# cslr_mcspi register map
Vendor: Texas Instruments
Peripheral module from a debugger description file (folder C5517).
Address unit: 16 bits
Registers are 16-bit, access not given, reset 0x0 unless marked. A register's access mark holds for its fields unless they carry their own. Offsets are as the file gives them; lines under a group give offsets from that group; [hi:lo] are bit positions; {n}, {i} and the like mark numbered series; 'fields as' and 'values as' point back to an identical list; <NAME> marks a mode.

## MCSPI — Master slave Multichannel Serial Port Interface
0x100 REVISIONL reset 0x2B — This register contains the hard coded RTL revision number
  [7:0] REV ro — IP revision [7:4] Major revision [3:0] Minor revision
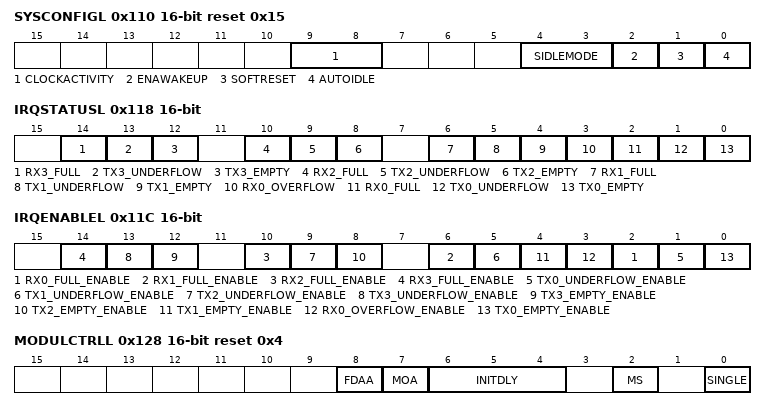
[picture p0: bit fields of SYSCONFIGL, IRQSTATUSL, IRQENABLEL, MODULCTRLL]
0x110 SYSCONFIGL reset 0x15 — This register allows controlling various parameters of the OCP interface. It is not sensitive to soft reset.
  [9:8] CLOCKACTIVITY rw — Clocks activity during wake up mode period
    0=ACT0 (OCP and Functional clocks may be switched off); 1=ACT1 (OCP clock is maintained. Functional clock may be switched-off); 2=ACT2 (Functional clock is maintained. OCP clock may be switched-off); 3=ACT3 (OCP and Functional clocks are maintained)
  [4:3] SIDLEMODE rw — Power management
    0=MODE0 (If an idle request is detected, the McSPI acknowledges it unconditionally and goes in Inactive mode. Interrupt, DMA requests and wake up lines are unconditionally de-asserted and the module wakeup capability is deactivated even if the bit MCSPI_SYSCONFIG[EnaWakeUp] is set); 1=MODE1 (If an idle request is detected, the request is ignored and the module does not switch to wake up mode, and keeps on behaving normally); 2=MODE2 (Smart-idle mode: local target's idle state eventually follows (acknowledges) the system's idle requests, depending on the IP module's internal requirements. IP module shall not generate (IRQ- or DMA-request-related) wakeup events); 3=MODE3 (IP module may generate (IRQ- or DMA-request-related) wakeup events when in idle state. Mode is only relevant if the appropriate IP module "swakeup" output(s) is (are) implemented)
  [2] ENAWAKEUP rw — WakeUp feature control
    0=DISABLE (WakeUp capability is disabled); 1=ENABLE (WakeUp capability is enabled)
  [1] SOFTRESET rw — Software reset. During reads it always returns 0.
    0=NORMAL (Normal mode); 1=TRIGGER (Set this bit to 1 to trigger a module reset.The bit is automatically reset by the hardware)
  [0] AUTOIDLE rw — Internal OCP Clock gating strategy
    0=FREERUN (OCP clock is free-running); 1=AUTO (Automatic OCP clock gating strategy is applied, based on the OCP interface activity)
0x114 SYSSTATUSL — This register provides status information about the module excluding the interrupt status information
  [0] RESETDONE ro — Internal Reset Monitoring
    0=ONGOING (Internal module reset is on-going); 1=COMPLETE (Reset completed)
0x118 IRQSTATUSL — The interrupt status regroups all the status of the module internal events that can generate an interrupt
  [all] fields
    0=FALSEEVT (w:Event status bit unchanged ,False event); 1=PENDINGEVT (w:Event status bit is reset ,r: Event is pending)
  [14] RX3_FULL rw — Receiver register is full or almost full. Only when Channel 3 is enabled
  [13] TX3_UNDERFLOW rw — Transmitter register underflow. Only when Channel 3 is enabled.
  [12] TX3_EMPTY rw — Transmitter register is empty or almost empty.
  [10] RX2_FULL rw — Receiver register full or almost full. Channel 2
  [9] TX2_UNDERFLOW rw — Transmitter register underflow. Channel 2
  [8] TX2_EMPTY rw — Transmitter register empty or almost empty. Channel 2
  [6] RX1_FULL rw — Receiver register full or almost full. Channel 1
  [5] TX1_UNDERFLOW rw — Transmitter register underflow. Channel 1
  [4] TX1_EMPTY rw — Transmitter register empty or almost empty. Channel 1
  [3] RX0_OVERFLOW rw — Receiver register overflow (slave mode only). Channel 0
  [2] RX0_FULL rw — Receiver register full or almost full. Channel 0
  [1] TX0_UNDERFLOW rw — Transmitter register underflow.Channel 0
  [0] TX0_EMPTY rw — Transmitter register empty or almost empty.Channel 0
0x119 IRQSTATUSU — The interrupt status regroups all the status of the module internal events that can generate an interrupt
  [1] EOW rw — End of word count event when a channel is enabled using the FIFO buffer and the channel had sent the number of SPI word defined by MCSPI_XFERLEVEL[WCNT].
    0=NOCHNAGE (w:Event status bit unchanged); 1=BITRESET (w:Event status bit is reset)
0x11C IRQENABLEL — This register allows to enable/disable the module internal sources of interrupt, on an event-by-event basis.
  [all] fields
    0=DISABLE (Interrupt disabled); 1=ENABLE (Interrupt enabled)
  [4n+2] RX{n}_FULL_ENABLE rw (n=0..3) — Receiver register Full or almost full Interrupt Enable. Ch {n}
  [4n+1] TX{n}_UNDERFLOW_ENABLE rw (n=0..3) — Transmitter register Underflow Interrupt Enable. Ch {n}
  [12] TX3_EMPTY_ENABLE rw — Transmitter register Empty or almost empty Interrupt Enable. Ch3
  [8] TX2_EMPTY_ENABLE rw — Transmitter register Empty or almost empty Interrupt Enable. Ch 2
  [4] TX1_EMPTY_ENABLE rw — Transmitter register Empty or almost empty Interrupt Enable. Ch 1
  [3] RX0_OVERFLOW_ENABLE rw — Receiver register Overflow Interrupt Enable. Ch 0
  [0] TX0_EMPTY_ENABLE rw — Transmitter register Empty or almost empty Interrupt Enable. Ch 0
0x11D IRQENABLEU — This register allows to enable/disable the module internal sources of interrupt, on an event-by-event basis.
  [1] EOWE rw — End of Word count Interrupt Enable
    0=DISABLE (Interrupt disabled); 1=ENABLE (Interrupt enabled)
0x120 WAKEUPENABLEL — The wakeup enable register allows to enable/disable the module internal sources of wakeup on event-by-event basis.
0x128 MODULCTRLL reset 0x4 — This register is dedicated to the configuration of the serial port interface.
  [8] FDAA rw — FIFO DMA Address 256-bit aligned
    0=TXREG (FIFO data managed by MCSPI_TX(i) and MCSPI_RX(i) registers); 1=DAFTXREG (FIFO data managed by MCSPI_DAFTX and MCSPI_DAFRX registers)
  [7] MOA rw — Multiple word ocp access
    0=DISABLE (Multiple word access disabled); 1=ENABLE (Multiple word access enabled with FIFO)
  [6:4] INITDLY rw — Initial spi delay for first transfer
    0=NODELAY (No delay for first spi transfer.); 1=4CLK (The controller wait 4 spi bus clock); 2=8CLK (The controller wait 8 spi bus clock); 3=16CLK (The controller wait 16 spi bus clock); 4=32CLK (The controller wait 32 spi bus clock)
  [2] MS rw — Master/ Slave
    0=MASTER (Master - The module generates the SPICLK and SPIEN[3:0]); 1=SLAVE (Slave - The module receives the SPICLK and SPIEN[3:0])
  [0] SINGLE rw — Single channel / Multi Channel (master mode only)
    0=MULTICH (More than one channel will be used in master mode); 1=SINGLECH (Only one channel will be used in master mode. This bit must be set in Force SPIEN mode)
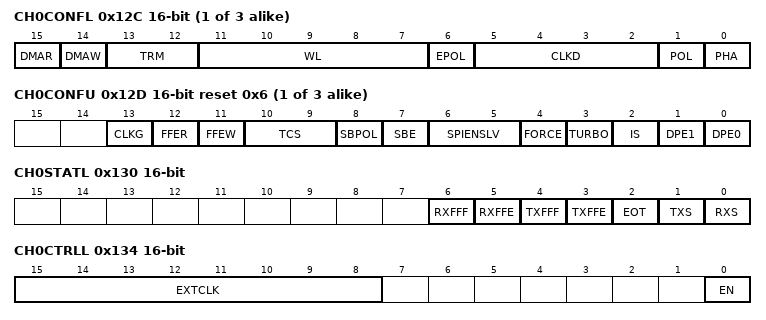
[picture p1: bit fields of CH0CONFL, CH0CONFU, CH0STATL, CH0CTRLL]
{0x12C+0x14*i} CH{i}CONFL rw (i=0..2) — This register is dedicated to the configuration of the channel {i}
  [15] DMAR — DMA Read request
    0=DISABLE (DMA Read Request disabled); 1=ENABLE (DMA Read Request enabled)
  [14] DMAW — DMA Write request
    0=DISABLE (DMA Write Request disabled); 1=ENABLE (DMA Write Request enabled)
  [13:12] TRM — Transmit/Receive modes
    0=MODE0 (Transmit and Receive mode); 1=MODE1 (Receive only mode); 2=MODE2 (Transmit only mode)
  [11:7] WL — SPI word length
    {v}={v+1}BIT (v=3..31)
  [6] EPOL — SPIEN polarity
    0=ACTIVEHIGH (SPIEN is held high during the active state); 1=ACTIVELOW (SPIEN is held low during the active state)
  [5:2] CLKD — Frequency divider for SPICLK
    0=DIV1; 1=DIV2; 2=DIV4; 3=DIV8; 4=DIV16; 5=DIV32; 6=DIV64; 7=DIV128; 8=DIV256; 9=DIV512; 10=DIV1024; 11=DIV2048; 12=DIV4096; 13=DIV8192; 14=DIV16384; 15=DIV32768
  [1] POL — SPICLK polarity
    0=ACTIVEHIGH (SPICLK is held high during the active state); 1=ACTIVELOW (SPICLK is held low during the active state)
  [0] PHA — SPICLK phase
    0=ODD (Data are latched on odd numbered edges of SPICLK.); 1=EVEN (Data are latched on even numbered edges of SPICLK.)
{0x12D+0x14*i} CH{i}CONFU reset 0x6 (i=0..2) — This register is dedicated to the configuration of the channel {i}
  [13] CLKG rw — Clock divider granularity
    0=GRAN0 (Clock granularity of power of two); 1=GRAN1 (One clock cycle ganularity)
  [12] FFER rw — FIFO enabled for receive
    0=FIFONOTUSED (The buffer is not used to receive data.); 1=FIFOUSED (The buffer is used to receive data)
  [11] FFEW rw — FIFO enabled for Transmit
    0=FIFONOTUSED (The buffer is not used to transmit data); 1=FIFOUSED (The buffer is used to transmit data.)
  [10:9] TCS rw — Chip Select Time Control
    0=TIME0 (0.5 clock cycle); 1=TIME1 (1.5 clock cycle); 2=TIME2 (2.5 clock cycle); 3=TIME3 (3.5 clock cycle)
  [8] SBPOL rw — Start bit polarity.
    0=ACTIVELOW (Star bit polarity is held to 0 during SPI transfer.); 1=ATIVEHIGH (Star bit polarity is held to 1 during SPI transfer)
  [7] SBE rw — Start bit enable for SPI transfer
    0=DEFAULT (Default SPI transfer length as specified by WL bit field); 1=ENABLE (Start bit D/CX added before SPI transfer, polarity is defined by MCSPI_CH(i)CONF[SBPOL])
  [6:5] SPIENSLV rw — Channel 0 only and slave mode only: SPI slave select signal detection
    {v}=DETSPIEN{v} (Detection enabled only on SPIEN[{v}]) (v=0..3)
  [4] FORCE rw — Manual SPIEN assertion to keep SPIEN active between SPI words
    0=SPIENLOW (Writing 0 into this bit drives low the SPIEN line when MCSPI_CHCONF(i)[EPOL]=0, and drives it high when MCSPI_CHCONF(i)[EPOL]=1); 1=SPIENHIGH (Writing 1 into this bit drives high the SPIEN line when MCSPI_CHCONF(i)[EPOL]=0, and drives it low when MCSPI_CHCONF(i)[EPOL]=1)
  [3] TURBO rw — Turbo mode
    0=DEACTIVATE (Turbo is deactivated (recommended for single SPI word transfer)); 1=ACTIVATE (Turbo is activated to maximize the throughput for multi SPI words transfer)
  [2] IS rw — Input Select
    0=LINE0 (Data Line0 (SPIDAT[0]) selected for reception); 1=LINE1 (Data Line1 (SPIDAT[1]) selected for reception)
  [1] DPE1 rw — Transmission Enable for data line 1
    0=DATLINE1 (Data Line1 (SPIDAT[1]) selected for transmission); 1=NOTRANSMISSON (No transmission on Data Line1 (SPIDAT[1]))
  [0] DPE0 rw — Transmission Enable for data line 0
    0=DATLINE0 (Data Line0 (SPIDAT[0]) selected for transmission); 1=NOTRANSMISSON (No transmission on Data Line0 (SPIDAT[0]))
0x130 CH0STATL — This register provides status information about transmitter and receiver registers of channel 0
  [6] RXFFF ro — FIFO Receive Buffer Full Status
    0=NOTFULL (FIFO Receive Buffer is not full); 1=FULL (FIFO Receive Buffer is full)
  [5] RXFFE ro — FIFO Receive Buffer Empty Status
    0=NOTEMPTY (FIFO Receive Buffer is not empty); 1=EMPTY (FIFO Receive Buffer is empty)
  [4] TXFFF ro — FIFO Transmit Buffer Full Status
    0=NOTFULL (FIFO Transmit Buffer is not full); 1=FULL (FIFO Transmit Buffer is full)
  [3] TXFFE ro — FIFO Transmit Buffer Empty Status
    0=NOTEMPTY (FIFO Tramsmit Buffer is not empty); 1=EMPTY (FIFO Transmit Buffer is empty)
  [2] EOT ro — End of transfer Status
    0=INPROGRESS (Shift register is loaded with the data from the transmitter register); 1=COMPLETED (End of an SPI transfer.)
  [1] TXS ro — Transmitter Register Status
    0=FULL (Register is full); 1=EMPTY (Register is empty)
  [0] RXS ro — Receiver Register Status
    0=EMPTY (Register is empty); 1=FULL (Register is full)
0x134 CH0CTRLL — This register is dedicated to enable the channel and defines the extended clock ratio with one clock cycle granularity
  [15:8] EXTCLK rw — Clock ratio extension
    0=CLKRATIO1 (Clock ratio is CLKD + 1); 1=CLKRATIO2 (Clock ratio is CLKD + 1 + 16); 2=CLKRATIO3 (Clock ratio is CLKD + 1 + 4080)
  [0] EN rw — Channel Enable
    0=DISABLE (Channel 0 disable); 1=ENABLE (Channel 0 enable)
0x138 TX0L rw — This register contains a single SPI word to transmit on the serial link, what ever SPI word length is.
  [15:0] TDATA — Data to transmit
0x139 TX0U rw — This register contains a single SPI word to transmit on the serial link, what ever SPI word length is.
  [15:0] TDATA — Data to transmit
0x13C RX0L ro — This register contains a single SPI word received through the serial link, what ever SPI word length is.
  [15:0] RDATA — Received Data
0x13D RX0U ro — This register contains a single SPI word received through the serial link, what ever SPI word length is.
  [15:0] RDATA — Received Data
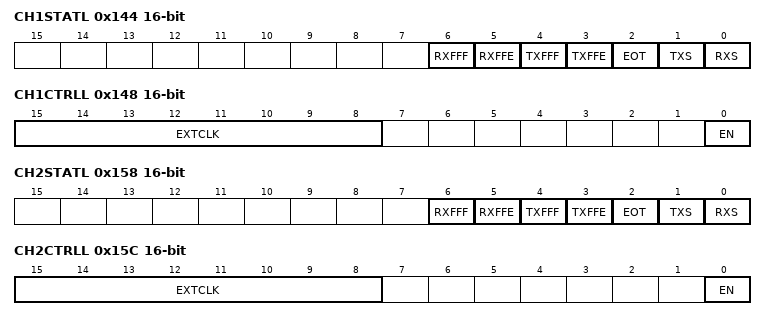
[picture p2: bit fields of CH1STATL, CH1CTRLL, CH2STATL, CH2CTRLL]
0x144 CH1STATL — This register provides status information about transmitter and receiver registers of channel 1
  [6] RXFFF ro — Channel 3 FIFO Receive Buffer Full Status
    values as CH0STATL.RXFFF
  [5] RXFFE ro — Channel 3 FIFO Receive Buffer Empty Status
    values as CH0STATL.RXFFE
  [4] TXFFF ro — Channel 3 FIFO Transmit Buffer Full Status
    values as CH0STATL.TXFFF
  [3] TXFFE ro — Channel 3 FIFO Transmit Buffer Empty Status
    values as CH0STATL.TXFFE
  [2] EOT ro — Channel 3 End of transfer Status
    values as CH0STATL.EOT
  [1] TXS ro — Channel 3 Transmitter Register Status
    0=FULL (Register is full); 1=EMPTY (Register is empty)
  [0] RXS ro — Channel 3 Receiver Register Status
    0=EMPTY (Register is empty); 1=FULL (Register is full)
0x148 CH1CTRLL — This register is dedicated to enable the channel and defines the extended clock ratio with one clock cycle granularity.
  [15:8] EXTCLK rw — Clock ratio extension
    values as CH0CTRLL.EXTCLK
  [0] EN rw — Channel Enable
    0=DISABLE (Channel 1 disable); 1=ENABLE (Channel 1 enable)
0x14C TX1L rw — This register contains a single SPI word to transmit on the serial link, what ever SPI word length is.
  [15:0] TDATA — Data to transmit
0x14D TX1U rw — This register contains a single SPI word to transmit on the serial link, what ever SPI word length is.
  [15:0] TDATA — Data to transmit
0x150 RX1L ro — This register contains a single SPI word received through the serial link, what ever SPI word length is.
  [15:0] RDATA — Received Data
0x151 RX1U ro — This register contains a single SPI word received through the serial link, what ever SPI word length is.
  [15:0] RDATA — Received Data
0x158 CH2STATL — This register provides status information about transmitter and receiver registers of channel 2
  fields as CH0STATL
0x15C CH2CTRLL — This register is dedicated to enable the channel and defines the extended clock ratio with one clock cycle granularity.
  [15:8] EXTCLK rw — Clock ratio extension
    values as CH0CTRLL.EXTCLK
  [0] EN rw — Channel Enable
    0=DISABLE (Channel 2 disable); 1=ENABLE (Channel 2 enable)
0x160 TX2L rw — This register contains a single SPI word to transmit on the serial link, what ever SPI word length is.
  [15:0] TDATA — Channel 2 Data to transmit
0x161 TX2U rw — This register contains a single SPI word to transmit on the serial link, what ever SPI word length is.
  [15:0] TDATA — Channel 2 Data to transmit
0x164 RX2L ro — This register contains a single SPI word received through the serial link, what ever SPI word length is.
  [15:0] RDATA — Channel 2 Received Data
0x165 RX2U ro — This register contains a single SPI word received through the serial link, what ever SPI word length is.
  [15:0] RDATA — Channel 2 Received Data
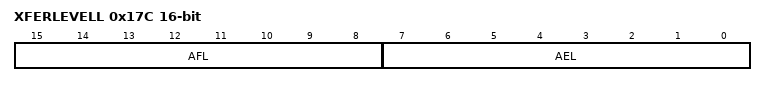
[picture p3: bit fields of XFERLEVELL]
0x17C XFERLEVELL rw — This register provides transfer levels needed while using FIFO buffer during transfer
  [15:8] AFL — Buffer Almost Full
  [7:0] AEL — Buffer Almost Empty
0x17D XFERLEVELU rw — This register provides transfer levels needed while using FIFO buffer during transfer
  [15:0] WCNT — Spi word counter
0x180 DAFTXL rw — This register contains the SPI words to transmit on the serial link when FIFO used and DMA address is aligned on 256 bit
  [15:0] DAFTDATA — FIFO Data to transmit with DMA 256 bit aligned address
0x181 DAFTXU rw — This register contains the SPI words to transmit on the serial link when FIFO used and DMA address is aligned on 256 bit
  fields as DAFTXL
0x1A0 DAFRXL ro — This register contains the SPI words to received on the serial link when FIFO used and DMA address is aligned on 256 bit.
  [15:0] DAFRDATA — FIFO Received Data with DMA 256 bit aligned address
0x1A1 DAFRXU ro — This register contains the SPI words to received on the serial link when FIFO used and DMA address is aligned on 256 bit.
  fields as DAFRXL
